# MK20DZ10 register map
Vendor: Freescale Semiconductor, Inc.; Series: Kinetis_K; File version: 1.6
CPU: CM4 r0p1, little endian, no MPU, no FPU, VTOR, 4 interrupt priority bits
Registers are 32-bit, read-write, reset 0x0 unless marked. A register's access mark holds for its fields unless they carry their own. Offsets are from the block's base; [hi:lo] are bit positions; {n}, {i} and the like mark numbered series.

## TSI0 — Touch Sensing Input
Base 0x40045000; register names take the prefix TSI0_
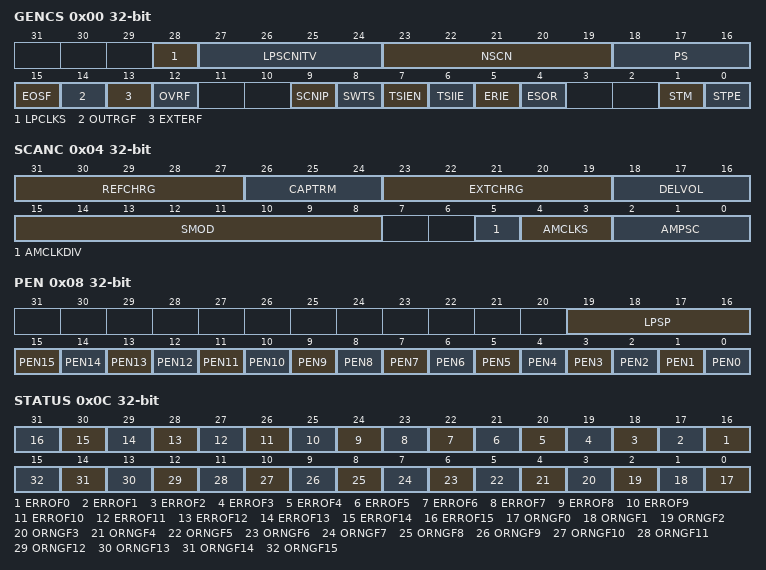
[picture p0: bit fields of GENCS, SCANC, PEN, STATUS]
0x00 GENCS — General Control and Status Register
  [28] LPCLKS — Low Power Mode Clock Source Selection
    0=LPOCLK; 1=VLPOSCCLK
  [27:24] LPSCNITV — TSI Low Power Mode Scan Interval
    0=1 ms scan interval; 1=5 ms scan interval; 2=10 ms scan interval; 3=15 ms scan interval; 4=20 ms scan interval; 5=30 ms scan interval; 6=40 ms scan interval; 7=50 ms scan interval; 8=75 ms scan interval; 9=100 ms scan interval; 10=125 ms scan interval; 11=150 ms scan interval; 12=200 ms scan interval; 13=300 ms scan interval; 14=400 ms scan interval; 15=500 ms scan interval
  [23:19] NSCN — Number of Consecutive Scans per Electrode
    0=1 time per electrode; {v}={v+1} times per electrode (v=1..31)
  [18:16] PS — Electrode oscillator prescaler
    0=Electrode oscillator frequency divided by 1; 1=Electrode oscillator frequency divided by 2; 2=Electrode oscillator frequency divided by 4; 3=Electrode oscillator frequency divided by 8; 4=Electrode oscillator frequency divided by 16; 5=Electrode oscillator frequency divided by 32; 6=Electrode oscillator frequency divided by 64; 7=Electrode oscillator frequency divided by 128
  [15] EOSF — End of scan flag
  [14] OUTRGF — Out of Range Flag
  [13] EXTERF — External electrode error occurred
    0=No short; 1=Short to VDD or VSS occured on the electrodes
  [12] OVRF — Overrun error flag
    0=No overrun; 1=Overrun occurred
  [9] SCNIP ro — Scan-in-progress status
  [8] SWTS wo — Software trigger start
  [7] TSIEN — TSI module enable
    0=TSI disabled; 1=TSI enabled
  [6] TSIIE — TSI interrupt enable
    0=Disable; 1=Enable
  [5] ERIE — TSI error interrupt Enable
    0=Error interrupt disabled; 1=Error interrupt enabled
  [4] ESOR — End-of-scan or out-of-range interrupt select
    0=Out-of-range interrupt selected; 1=End-of-scan interrupt selected
  [1] STM — Scan trigger mode
    0=Software trigger scan; 1=Periodical scan
  [0] STPE
    0=Disable TSI when MCU enters low-power modes; 1=Allow TSI to continue running in all low power modes
0x04 SCANC — SCAN control register
  [31:27] REFCHRG — Reference oscillator charge current select
    {v}={v+1} uA charge current (v=0..31)
  [26:24] CAPTRM — Internal capacitance trim value
    0=0.5 pF internal reference capacitance; 1=0.6 pF internal reference capacitance; 2=0.7 pF internal reference capacitance; 3=0.8 pF internal reference capacitance; 4=0.9 pF internal reference capacitance; 5=1.0 pF internal reference capacitance; 6=1.1 pF internal reference capacitance; 7=1.2 pF internal reference capacitance
  [23:19] EXTCHRG — External oscillator charge current select
    {v}={v+1} uA charge current (v=0..31)
  [18:16] DELVOL — Delta voltage select applied to analog oscillators
    0=100 mV delta voltage is applied; 1=150 mV delta voltage is applied; 2=200 mV delta voltage is applied; 3=250 mV delta voltage is applied; 4=300 mV delta voltage is applied; 5=400 mV delta voltage is applied; 6=500 mV delta voltage is applied; 7=600 mV delta voltage is applied
  [15:8] SMOD — Scan modulo
    0=Continuous scan
  [5] AMCLKDIV — Active mode clock divider
    0=Divider set to 1; 1=Divider set to 2048
  [4:3] AMCLKS — Active mode clock source
    0=Bus Clock; 1=MCGIRCLK; 2=OSCERCLK; 3=Not valid
  [2:0] AMPSC — Active mode prescaler
    0=Input clock source divided by 1; 1=Input clock source divided by 2; 2=Input clock source divided by 4; 3=Input clock source divided by 8; 4=Input clock source divided by 16; 5=Input clock source divided by 32; 6=Input clock source divided by 64; 7=Input clock source divided by 128
0x08 PEN — Pin enable register
  [19:16] LPSP — Low-power scan pin
    {v}=TSI_IN[{v}] is active in low power mode (v=0..15)
  [n] PEN{n} (n=0..15) — TSI pin {n} enable
    0=The corresponding pin is not used by TSI; 1=The corresponding pin is used by TSI
0x0C STATUS
  [n+16] ERROF{n} (n=0..15) — TouchSensing Error Flag {n}
  [n] ORNGF{n} (n=0..15) — Touch Sensing Electrode Out-of-Range Flag {n}
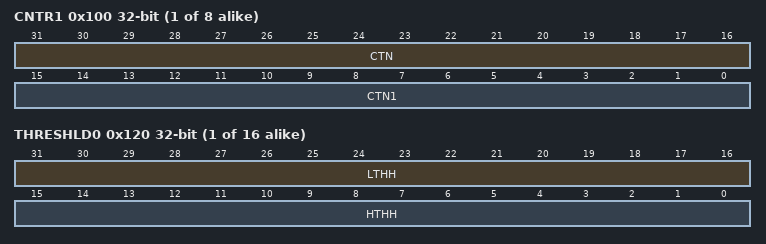
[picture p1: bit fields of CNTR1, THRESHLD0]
0x100 CNTR{x} (x=1,3,5,7,9,11,13,15; step 0x4) ro — Counter Register
  [31:16] CTN — Touch sensing channel n counter value.
  [15:0] CTN1 — Touch sensing channel n-1 counter value.
{0x120+4i} THRESHLD{i} (i=0..15) — Channel n threshold register
  [31:16] LTHH — Low threshold value
  [15:0] HTHH — High threshold value

## Notices in the file
Redistribution and use in source and binary forms, with or without modification,
are permitted provided that the following conditions are met:
o Redistributions of source code must retain the above copyright notice, this list
of conditions and the following disclaimer.
o Redistributions in binary form must reproduce the above copyright notice, this
list of conditions and the following disclaimer in the documentation and/or
other materials provided with the distribution.
o Neither the name of Freescale Semiconductor, Inc. nor the names of its
contributors may be used to endorse or promote products derived from this
software without specific prior written permission.
THIS SOFTWARE IS PROVIDED BY THE COPYRIGHT HOLDERS AND CONTRIBUTORS "AS IS" AND
ANY EXPRESS OR IMPLIED WARRANTIES, INCLUDING, BUT NOT LIMITED TO, THE IMPLIED
WARRANTIES OF MERCHANTABILITY AND FITNESS FOR A PARTICULAR PURPOSE ARE
DISCLAIMED. IN NO EVENT SHALL THE COPYRIGHT HOLDER OR CONTRIBUTORS BE LIABLE FOR
ANY DIRECT, INDIRECT, INCIDENTAL, SPECIAL, EXEMPLARY, OR CONSEQUENTIAL DAMAGES
(INCLUDING, BUT NOT LIMITED TO, PROCUREMENT OF SUBSTITUTE GOODS OR SERVICES;
LOSS OF USE, DATA, OR PROFITS; OR BUSINESS INTERRUPTION) HOWEVER CAUSED AND ON
ANY THEORY OF LIABILITY, WHETHER IN CONTRACT, STRICT LIABILITY, OR TORT
(INCLUDING NEGLIGENCE OR OTHERWISE) ARISING IN ANY WAY OUT OF THE USE OF THIS
SOFTWARE, EVEN IF ADVISED OF THE POSSIBILITY OF SUCH DAMAGE.
